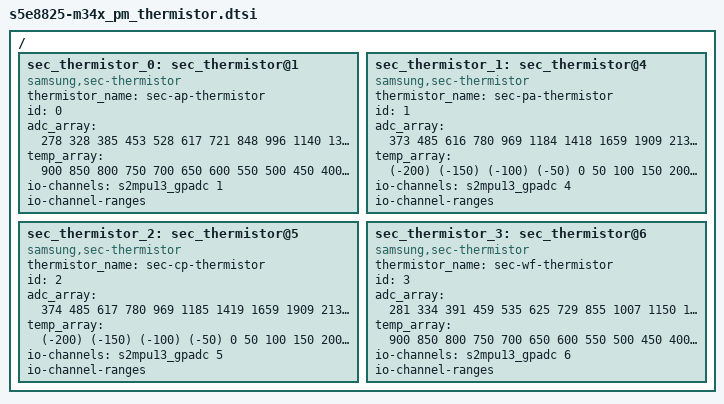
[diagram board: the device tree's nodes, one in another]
/*
 * SAMSUNG S5E8825 Power Management device tree source
 *
 * Copyright (c) 2026 Samsung Electronics Co., Ltd.
 *		http://www.samsung.com
 *
 * This program is free software; you can redistribute it and/or modify
 * it under the terms of the GNU General Public License version 2 as
 * published by the Free Software Foundation.
 */

/ {
	fragment@model {
		target-path = "/";
		__overlay__ {
			sec_thermistor_0: sec_thermistor@1 {
				compatible = "samsung,sec-thermistor";
				status = "okay";
				thermistor_name = "sec-ap-thermistor";
				id = <0>;

				adc_array = <278 328 385 453 528 617 721 848 996 1140
					1331 1480 1702 1937 2162 2413 2653 2890 3107 3296
					3464 3594 3707>;
				temp_array = <900 850 800 750 700 650 600 550 500 450
					  400 350 300 250 200 150 100 50 0 (-50)
					  (-100) (-150) (-200)>;

				io-channels = <&s2mpu13_gpadc 1>;
				io-channel-names = "adc-ap-temp";
				io-channel-ranges;
			};

			sec_thermistor_1: sec_thermistor@4 {
				compatible = "samsung,sec-thermistor";
				status = "okay";
				thermistor_name = "sec-pa-thermistor";
				id = <1>;

				adc_array = <373 485 616 780 969 1184 1418 1659 1909 2134
					2371 2594 2744 2936 3080 3232 3360 3464 3555 3630
					3698 3756 3804>;
				temp_array = <(-200) (-150) (-100) (-50) 0 50 100 150 200 250
					300 350 400 450 500 550 600 650 700 750
					800 850 900>;

				io-channels = <&s2mpu13_gpadc 4>;
				io-channel-names = "adc-pa-temp";
				io-channel-ranges;
			};

			sec_thermistor_2: sec_thermistor@5 {
				compatible = "samsung,sec-thermistor";
				status = "okay";
				thermistor_name = "sec-cp-thermistor";
				id = <2>;

				adc_array = <374 485 617 780 969 1185 1419 1659 1909 2134
					2371 2594 2744 2936 3080 3232 3360 3464 3554 3630
					3698 3755 3808>;
				temp_array = <(-200) (-150) (-100) (-50) 0 50 100 150 200 250
					300 350 400 450 500 550 600 650 700 750
					800 850 900>;

				io-channels = <&s2mpu13_gpadc 5>;
				io-channel-names = "adc-cp-temp";
				io-channel-ranges;
			};

			sec_thermistor_3: sec_thermistor@6 {
				compatible = "samsung,sec-thermistor";
				status = "okay";
				thermistor_name = "sec-wf-thermistor";
				id = <3>;

				adc_array = <281 334 391 459 535 625 729 855 1007 1150
					1341 1491 1713 1949 2174 2425 2666 2901 3119 3308
					3472 3603 3716>;
				temp_array = <900 850 800 750 700 650 600 550 500 450
					  400 350 300 250 200 150 100 50 0 (-50)
					  (-100) (-150) (-200)>;

				io-channels = <&s2mpu13_gpadc 6>;
				io-channel-names = "adc-wf-temp";
				io-channel-ranges;
			};
		}; /* end of __overlay__ */
	}; /* end of fragment */
}; /* end of root */
